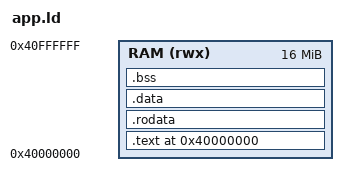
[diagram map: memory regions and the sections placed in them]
/*
 * Linker Script for VinixOS User Programs
 * Memory layout: Base address 0x40000000
 */

ENTRY(_start)

MEMORY
{
    RAM (rwx) : ORIGIN = 0x40000000, LENGTH = 16M
}

SECTIONS
{
    . = 0x40000000;
    
    .text : {
        *(.text)
        *(.text.*)
    } > RAM
    
    .rodata : {
        *(.rodata)
        *(.rodata.*)
    } > RAM
    
    .data : {
        *(.data)
        *(.data.*)
    } > RAM
    
    .bss : {
        *(.bss)
        *(.bss.*)
        *(COMMON)
    } > RAM
    
    /DISCARD/ : {
        *(.comment)
        *(.note*)
        *(.ARM.attributes)
    }
}
